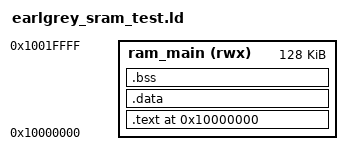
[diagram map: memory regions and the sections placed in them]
/* Minimal linker script for a bare-metal test payload loaded into Earl Grey main SRAM.
 * Memory addresses from vendor/opentitan/hw/top_earlgrey/sw/autogen/top_earlgrey_memory.ld
 * (autogenerated from hw/top_earlgrey/data/top_earlgrey.hjson).
 *
 * The TEST ROM brings the chip out of reset and jumps to ORIGIN(ram_main).
 * This script places .text first so that the reset target lands in code.
 * No CRT0 here — trainees supply main(); the TEST ROM handles startup.
 */

OUTPUT_ARCH(riscv)
__DYNAMIC = 0;

MEMORY {
  /* Earl Grey main SRAM: 128 KiB at 0x1000_0000 */
  ram_main (rwx) : ORIGIN = 0x10000000, LENGTH = 0x20000
}

ENTRY(main)

SECTIONS {
  .text ORIGIN(ram_main) : ALIGN(4) {
    *(.text .text.*)
    *(.rodata .rodata.*)
    . = ALIGN(4);
  } > ram_main

  .data : ALIGN(4) {
    *(.data .data.*)
    *(.sdata .sdata.*)
    . = ALIGN(4);
  } > ram_main

  .bss : ALIGN(4) {
    *(.bss .bss.*)
    *(.sbss .sbss.*)
    . = ALIGN(4);
  } > ram_main

  /* Discard metadata not needed for a bare binary image */
  /DISCARD/ : {
    *(.riscv.attributes)
    *(.comment)
  }
}
